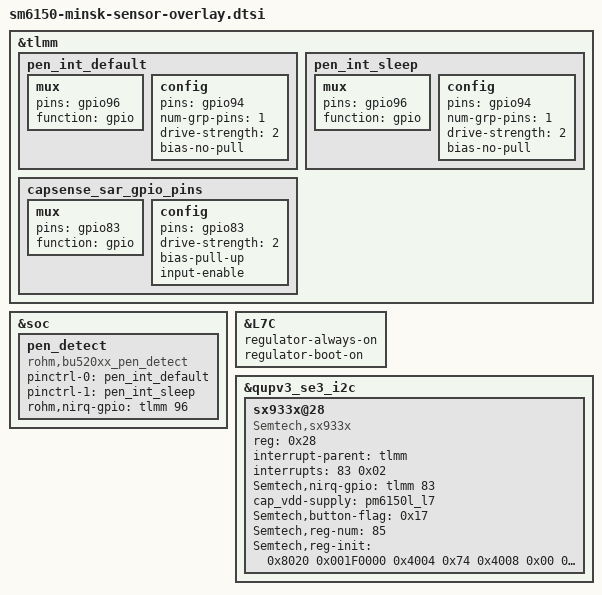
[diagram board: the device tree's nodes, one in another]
/* Copyright (c) 2018, The Linux Foundation. All rights reserved.
 *
 * This program is free software; you can redistribute it and/or modify
 * it under the terms of the GNU General Public License version 2 and
 * only version 2 as published by the Free Software Foundation.
 *
 * This program is distributed in the hope that it will be useful,
 * but WITHOUT ANY WARRANTY; without even the implied warranty of
 * MERCHANTABILITY or FITNESS FOR A PARTICULAR PURPOSE.  See the
 * GNU General Public License for more details.
 */
&tlmm {
	pen_int_default: pen_int_default {
			mux {
				pins = "gpio96";
				function =  "gpio";
			};
			config {
				pins = "gpio94";
				num-grp-pins = <1>;
				drive-strength = <2>;
				bias-no-pull;
			};
	};

	pen_int_sleep: pen_int_sleep {
			mux {
				pins = "gpio96";
				function =  "gpio";
			};
			config {
				pins = "gpio94";
				num-grp-pins = <1>;
				drive-strength = <2>;
				bias-no-pull;
			};
	};

	capsense_sar_gpio_pins: capsense_sar_gpio_pins {
		mux {
			pins = "gpio83";
			function = "gpio";
		};
		config {
			pins = "gpio83";
			drive-strength = <2>;
			bias-pull-up; /* PULL UP*/
			input-enable;
		};
	};
};

&soc {
	pen_detect{
		compatible = "rohm,bu520xx_pen_detect";
		pinctrl-names = "default","sleep";
		pinctrl-0 = <&pen_int_default>;
		pinctrl-1 = <&pen_int_sleep>;
		rohm,nirq-gpio=<&tlmm 96 0x02>;
	};
};

&L7C{
		regulator-always-on;
		regulator-boot-on;
};

&qupv3_se3_i2c {
	status = "ok";

	sx933x@28 {
		compatible = "Semtech,sx933x";
		reg = <0x28>;
		interrupt-parent = <&tlmm>;
		interrupts = <83 0x02>;
		Semtech,nirq-gpio = <&tlmm 83 0x02>;
		cap_vdd-supply = <&pm6150l_l7>;
		Semtech,button-flag = <0x17>;
		Semtech,reg-num = <85>;
		Semtech,reg-init = <
			0x8020 0x001F0000
			0x4004 0x74
			0x4008 0x00
			0x4054 0x400
			0x42C0 0x8000000
			0x42C4 0x3F
			0x800C 0x00
			0x8010 0x00
			0x8014 0x00
			0x8018 0x00
			0x801C 0x31
			0x8024 0x10000A6E
			0x8028 0x2FFF82C8
			0x802C 0x10000A6E
			0x8030 0x3FF7825F
			0x8034 0xA66
			0x8038 0x3FBF82C3
			0x803C 0x10000A5E
			0x8040 0x3DFF8263
			0x8044 0xA66
			0x8048 0x3FFE82C0
			0x804C 0x88E
			0x8050 0x80001EE6
			0x8054 0x10223705
			0x8058 0x20630031
			0x805C 0x78A45000
			0x8060 0x00
			0x8064 0x6D0000
			0x8068 0x00
			0x806C 0x00
			0x8070 0x00
			0x8074 0x10223705
			0x8078 0x20630031
			0x807C 0x789C5000
			0x8080 0x00
			0x8084 0x700000
			0x8088 0x00
			0x808C 0x21002100
			0x8090 0x10000
			0x8094 0x10222605
			0x8098 0x20630031
			0x809C 0x789C5000
			0x80A0 0x00
			0x80A4 0x440000
			0x80A8 0x00
			0x80AC 0x21002100
			0x80B0 0x10000
			0x80B4 0x1052FF00
			0x80B8 0x20630031
			0x80BC 0x54AC5300
			0x80C0 0x00
			0x80C4 0x00
			0x80C8 0x00
			0x80CC 0x00
			0x80D0 0x00
			0x80D4 0x10224400
			0x80D8 0x20630031
			0x80DC 0x789C5000
			0x80E0 0x00
			0x80E4 0x00
			0x80E8 0x00
			0x80EC 0x00
			0x80F0 0x00
			0x80F4 0x10162800
			0x80F8 0x20400031
			0x80FC 0x54AC5300
			0x8100 0x00
			0x8104 0x00
			0x8108 0x00
			0x810C 0x00
			0x8110 0x00
			0x8124 0x400000B
			0x8128 0x0C
			0x812C 0x00
			0x8130 0x00
			0x8134 0x00
			0x8138 0x00
			0x813C 0x00
			0x8140 0x00
			0x8144 0x00
			0x8148 0x00
			0x814C 0x00
			0x81A4 0x1C40011
			0x8020 0x001F001F
			0x4280 0x000F
			>;

		status = "ok";
	};
};
